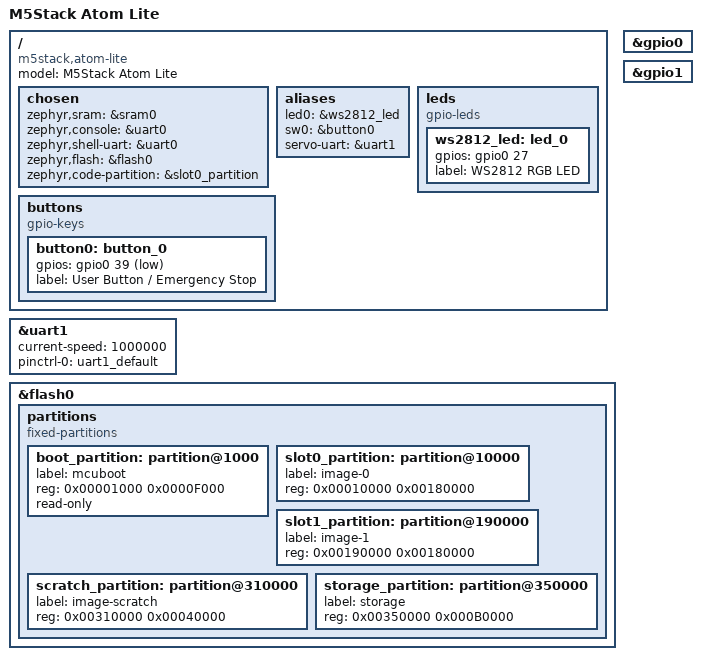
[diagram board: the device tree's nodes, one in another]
/*
 * M5Stack Atom Lite Device Tree
 * Copyright (c) 2026 OctroBot Project
 *
 * SPDX-License-Identifier: Apache-2.0
 *
 * Board: M5Stack Atom Lite
 * SoC: ESP32-PICO-D4
 * Features:
 *   - ESP32 dual-core @ 240MHz
 *   - 4MB Flash
 *   - 520KB SRAM
 *   - USB-C (CH340C USB-UART bridge to UART0)
 *   - WS2812 RGB LED (GPIO 27)
 *   - Button (GPIO 39)
 *   - Custom UART (GPIO 21=TX, GPIO 25=RX - Servo bus)
 */

/dts-v1/;

#include <espressif/esp32/esp32_pico_d4.dtsi>
#include "m5stack_atom_lite-pinctrl.dtsi"

/ {
	model = "M5Stack Atom Lite";
	compatible = "m5stack,atom-lite", "espressif,esp32";

	chosen {
		zephyr,sram = &sram0;
		zephyr,console = &uart0;
		zephyr,shell-uart = &uart0;
		zephyr,flash = &flash0;
		zephyr,code-partition = &slot0_partition;
	};

	aliases {
		led0 = &ws2812_led;
		sw0 = &button0;
		servo-uart = &uart1;
	};

	leds {
		compatible = "gpio-leds";
		
		/* WS2812B RGB LED - requires special driver, placeholder as GPIO */
		ws2812_led: led_0 {
			gpios = <&gpio0 27 GPIO_ACTIVE_HIGH>;
			label = "WS2812 RGB LED";
		};
	};

	buttons {
		compatible = "gpio-keys";
		
		button0: button_0 {
			gpios = <&gpio0 39 (GPIO_PULL_UP | GPIO_ACTIVE_LOW)>;
			label = "User Button / Emergency Stop";
		};
	};
};

/* UART1 for Feetech servo bus (GPIO21=TX, GPIO25=RX) */
&uart1 {
	status = "okay";
	current-speed = <1000000>; /* 1 Mbps for Feetech STS servos */
	pinctrl-0 = <&uart1_default>;
	pinctrl-names = "default";
};

/* Flash partitions */
&flash0 {
	partitions {
		compatible = "fixed-partitions";
		#address-cells = <1>;
		#size-cells = <1>;

		/* Reserve 64KB for bootloader */
		boot_partition: partition@1000 {
			label = "mcuboot";
			reg = <0x00001000 0x0000F000>;
			read-only;
		};

		/* Application slot 0 - 1.5MB */
		slot0_partition: partition@10000 {
			label = "image-0";
			reg = <0x00010000 0x00180000>;
		};

		/* Application slot 1 - 1.5MB (for future OTA updates) */
		slot1_partition: partition@190000 {
			label = "image-1";
			reg = <0x00190000 0x00180000>;
		};

		/* Scratch partition for OTA - 256KB */
		scratch_partition: partition@310000 {
			label = "image-scratch";
			reg = <0x00310000 0x00040000>;
		};

		/* Storage partition - 704KB */
		storage_partition: partition@350000 {
			label = "storage";
			reg = <0x00350000 0x000B0000>;
		};
	};
};

/* GPIO configuration */
&gpio0 {
	status = "okay";
};

&gpio1 {
	status = "okay";
};
